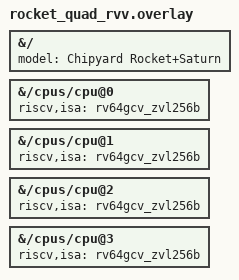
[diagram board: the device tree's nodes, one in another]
#include "rocket_quad.overlay"
&{/} { model = "Chipyard Rocket+Saturn"; };
&{/cpus/cpu@0} { riscv,isa = "rv64gcv_zvl256b"; };
&{/cpus/cpu@1} { riscv,isa = "rv64gcv_zvl256b"; };
&{/cpus/cpu@2} { riscv,isa = "rv64gcv_zvl256b"; };
&{/cpus/cpu@3} { riscv,isa = "rv64gcv_zvl256b"; };
